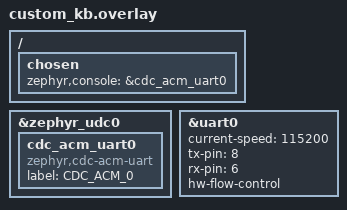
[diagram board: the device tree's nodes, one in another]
/ {
    chosen {
        zephyr,console = &cdc_acm_uart0;
    };
};

&zephyr_udc0 {
    cdc_acm_uart0: cdc_acm_uart0 {
        compatible = "zephyr,cdc-acm-uart";
        label = "CDC_ACM_0";
    };
};

&uart0 {
    status        = "okay";
    current-speed = <115200>;
    tx-pin        = <8>;  /* P0.08 ← STM32 PA11 */
    rx-pin        = <6>;  /* P0.06 → STM32 PA12 */
    hw-flow-control;
};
